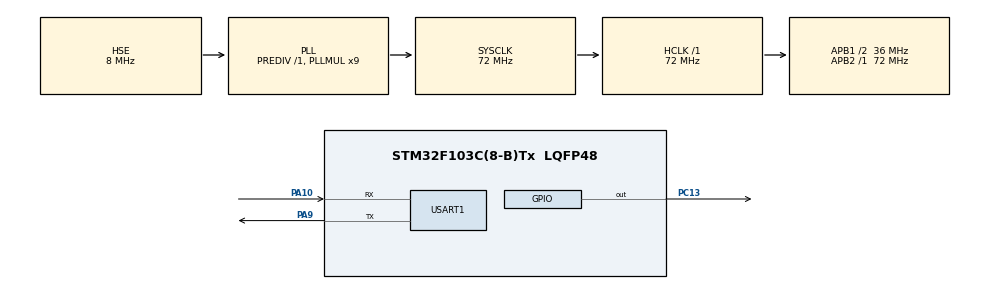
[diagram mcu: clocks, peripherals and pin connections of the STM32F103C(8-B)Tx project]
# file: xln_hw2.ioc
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Mcu.Family=STM32F1
Mcu.Name=STM32F103C(8-B)Tx
Mcu.Package=LQFP48
NVIC.PriorityGroup=NVIC_PRIORITYGROUP_4
NVIC.TIM1_BRK_IRQn=true\:0\:0\:false\:false\:true\:true\:true\:true
NVIC.TIM1_CC_IRQn=true\:0\:0\:false\:false\:true\:true\:true\:true
NVIC.TIM1_TRG_COM_IRQn=true\:0\:0\:false\:false\:true\:true\:true\:true
NVIC.TIM1_UP_IRQn=true\:0\:0\:false\:false\:true\:true\:true\:true
NVIC.USART1_IRQn=true\:0\:0\:false\:false\:true\:true\:true\:true
PA10.Mode=Asynchronous
PA10.Signal=USART1_RX
PA13.Mode=Serial_Wire
PA13.Signal=SYS_JTMS-SWDIO
PA14.Mode=Serial_Wire
PA14.Signal=SYS_JTCK-SWCLK
PA9.Mode=Asynchronous
PA9.Signal=USART1_TX
PC13-TAMPER-RTC.GPIO_ModeDefaultOutputPP=GPIO_MODE_OUTPUT_PP
PC13-TAMPER-RTC.GPIO_PuPd=GPIO_PULLUP
PC13-TAMPER-RTC.GPIO_Speed=GPIO_SPEED_FREQ_HIGH
PC13-TAMPER-RTC.PinState=GPIO_PIN_SET
PC13-TAMPER-RTC.Signal=GPIO_Output
PD0-OSC_IN.Mode=HSE-External-Oscillator
PD0-OSC_IN.Signal=RCC_OSC_IN
PD1-OSC_OUT.Mode=HSE-External-Oscillator
PD1-OSC_OUT.Signal=RCC_OSC_OUT
ProjectManager.HeapSize=0x200
ProjectManager.StackSize=0x400
ProjectManager.TargetToolchain=MDK-ARM V5.32
RCC.AHBFreq_Value=72000000
RCC.APB1CLKDivider=RCC_HCLK_DIV2
RCC.APB1Freq_Value=36000000
RCC.APB1TimFreq_Value=72000000
RCC.APB2Freq_Value=72000000
RCC.APB2TimFreq_Value=72000000
RCC.HCLKFreq_Value=72000000
RCC.PLLMUL=RCC_PLL_MUL9
RCC.PLLSourceVirtual=RCC_PLLSOURCE_HSE
RCC.SYSCLKFreq_VALUE=72000000
RCC.SYSCLKSource=RCC_SYSCLKSOURCE_PLLCLK
RCC.USBFreq_Value=72000000
TIM1.AutoReloadPreload=TIM_AUTORELOAD_PRELOAD_ENABLE
TIM1.Prescaler=72-1
USART1.VirtualMode=VM_ASYNC
VP_TIM1_VS_ClockSourceINT.Mode=Internal
board=custom

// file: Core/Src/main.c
/* USER CODE BEGIN Header */
/**
  ******************************************************************************
  * @file           : main.c
  * @brief          : Main program body
  ******************************************************************************
  * @attention
  *
  * Copyright (c) 2023 STMicroelectronics.
  * All rights reserved.
  *
  * This software is licensed under terms that can be found in the LICENSE file
  * in the root directory of this software component.
  * If no LICENSE file comes with this software, it is provided AS-IS.
  *
  ******************************************************************************
  */
/* USER CODE END Header */
#include "main.h"
#include "tim.h"
#include "usart.h"
#include "gpio.h"

/* USER CODE BEGIN Includes */
#include<stdio.h>
#include<string.h>

/* USER CODE END Includes */

/* USER CODE BEGIN PV */
void delay_us(uint16_t us);
void delay_ms(uint16_t ms);

/* USER CODE END PV */

void SystemClock_Config(void);

/* USER CODE BEGIN 0 */

//int fputc(int ch, FILE *f)
//{
//   HAL_UART_Transmit(&huart1, (uint8_t *)&ch, 1, 0xffff);
//   return ch;
//}

//int fgetc(FILE *f)
//{
//   uint8_t ch = 0;
//   HAL_UART_Receive(&huart1, &ch, 1, 0xffff);
//   return ch;
//}

/* USER CODE END 0 */

int main(void)
{

  /* MCU Configuration--------------------------------------------------------*/

  /* Reset of all peripherals, Initializes the Flash interface and the Systick. */
  HAL_Init();

  /* Configure the system clock */
  SystemClock_Config();

  /* Initialize all configured peripherals */
  MX_GPIO_Init();
  MX_TIM1_Init();
  MX_USART1_UART_Init();
  /* USER CODE BEGIN 2 */

	__HAL_UART_ENABLE_IT(&huart1,UART_IT_RXNE);
	HAL_GPIO_WritePin(GPIOC,GPIO_PIN_13,GPIO_PIN_RESET);
	uint8_t Data_1[12]="Hello World\n";
	HAL_UART_Transmit(&huart1, (uint8_t*)Data_1,strlen("Hello World\n"),0xFFFF);
	//HAL_UART_Receive(&huart1,(uint8_t*)Data_1,strlen("Hello World\n"),0xFFFF);

  /* USER CODE END 2 */

  /* Infinite loop */
  while (1)
  {

    /* USER CODE BEGIN 3 */

	//#ifdef mode_1

	uint8_t Rxbuffer2[8]="Running!";
	HAL_UART_Transmit(&huart1, (uint8_t*)Rxbuffer2,strlen("Running!"),0xFFFF);
	int i;
	for(i=0;i<1000;i++)
		{
		delay_us(1000);
	  }
	//#endif

		#ifdef mode_3

		#endif
  }
  /* USER CODE END 3 */
}

void SystemClock_Config(void)
{
  RCC_OscInitTypeDef RCC_OscInitStruct = {0};
  RCC_ClkInitTypeDef RCC_ClkInitStruct = {0};

  /** Initializes the RCC Oscillators according to the specified parameters
  * in the RCC_OscInitTypeDef structure.
  */
  RCC_OscInitStruct.OscillatorType = RCC_OSCILLATORTYPE_HSE;
  RCC_OscInitStruct.HSEState = RCC_HSE_ON;
  RCC_OscInitStruct.HSEPredivValue = RCC_HSE_PREDIV_DIV1;
  RCC_OscInitStruct.HSIState = RCC_HSI_ON;
  RCC_OscInitStruct.PLL.PLLState = RCC_PLL_ON;
  RCC_OscInitStruct.PLL.PLLSource = RCC_PLLSOURCE_HSE;
  RCC_OscInitStruct.PLL.PLLMUL = RCC_PLL_MUL9;
  if (HAL_RCC_OscConfig(&RCC_OscInitStruct) != HAL_OK)
  {
    Error_Handler();
  }

  /** Initializes the CPU, AHB and APB buses clocks
  */
  RCC_ClkInitStruct.ClockType = RCC_CLOCKTYPE_HCLK|RCC_CLOCKTYPE_SYSCLK
                              |RCC_CLOCKTYPE_PCLK1|RCC_CLOCKTYPE_PCLK2;
  RCC_ClkInitStruct.SYSCLKSource = RCC_SYSCLKSOURCE_PLLCLK;
  RCC_ClkInitStruct.AHBCLKDivider = RCC_SYSCLK_DIV1;
  RCC_ClkInitStruct.APB1CLKDivider = RCC_HCLK_DIV2;
  RCC_ClkInitStruct.APB2CLKDivider = RCC_HCLK_DIV1;

  if (HAL_RCC_ClockConfig(&RCC_ClkInitStruct, FLASH_LATENCY_2) != HAL_OK)
  {
    Error_Handler();
  }
}

/* USER CODE BEGIN 4 */

	#ifdef mode_2

void HAL_UART_RxCpltCallback(&huart1)

void HAL_UART_Receive_IT(&huart1, uint8_t *pData, uint16_t Size);
	{

	}

	#endif

void delay_us(uint16_t us)  //us delay function
{
	uint16_t counter = 0;
	__HAL_TIM_SetAutoreload(&htim1, us);
	__HAL_TIM_SetCounter(&htim1, counter);
	HAL_TIM_Base_Start(&htim1);
	while(counter != us)
	{
		counter = __HAL_TIM_GetCounter(&htim1);
	}
	HAL_TIM_Base_Stop(&htim1);
}

void delay_ms(uint16_t ms)  //ms delay function
{
	int n;
	for(n=0;n<1000;n++)
	{
		delay_us(1000);
	}
}

/* USER CODE END 4 */

void Error_Handler(void)
{
  __disable_irq();
  while (1)
  {
  }
}
